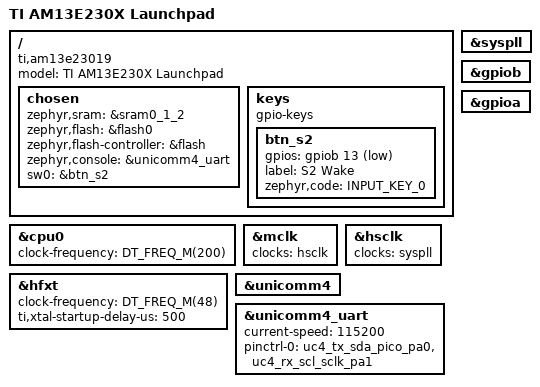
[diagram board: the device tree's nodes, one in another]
/*
 * Copyright (c) 2026 Texas Instruments Incorporated
 *
 * SPDX-License-Identifier: Apache-2.0
 */

/dts-v1/;

#include <ti/am13/am13e23019.dtsi>
#include <ti/am13/am13e23019-pinctrl.dtsi>
#include <zephyr/dt-bindings/gpio/gpio.h>
#include <zephyr/dt-bindings/input/input-event-codes.h>

/ {
	model = "TI AM13E230X Launchpad";
	compatible = "ti,am13e23019";

	chosen {
		zephyr,sram = &sram0_1_2;
		zephyr,flash = &flash0;
		zephyr,flash-controller = &flash;
		zephyr,console = &unicomm4_uart;
		sw0 = &btn_s2;
	};

	keys {
		compatible = "gpio-keys";

		/* S2: user wake/GPIO button — PB13, active low, external pull-up
		 * (LP-AM13E230 UG Table 3-x, net WAKE_GPIO / S2). */
		btn_s2: btn_s2 {
			gpios = <&gpiob 13 (GPIO_ACTIVE_LOW | GPIO_PULL_UP)>;
			label = "S2 Wake";
			zephyr,code = <INPUT_KEY_0>;
		};
	};
};

&cpu0 {
	clock-frequency = <DT_FREQ_M(200)>;
};

&mclk {
	clocks = <&hsclk>;
};

&hsclk {
	clocks = <&syspll>;
	status = "okay";
};

&syspll {
	status = "okay";
};

&hfxt {
	clock-frequency = <DT_FREQ_M(48)>;
	ti,xtal-startup-delay-us = <500>;
};

&gpiob {
	status = "okay";
};

&gpioa {
	status = "okay";
};

&unicomm4 {
	status = "okay";
};

&unicomm4_uart {
	status = "okay";
	current-speed = <115200>;
	pinctrl-0 = <&uc4_tx_sda_pico_pa0 &uc4_rx_scl_sclk_pa1>;
	pinctrl-names = "default";
};

// &unicomm3 {
// 	status = "okay";
// };

// /*
//  * CS is software (GPIO) controlled so the SPI context can keep it asserted
//  * throughout the entire pixel-data burst.  PA21 is NOT muxed to the UNICOMM
//  * CTS/CS0 function — it stays as a plain GPIO driven by the SPI context.
//  */
// &unicomm3_spi {
// 	status = "okay";
// 	pinctrl-0 = <&uc3_rx_scl_sclk_pb5
// 	             &uc3_tx_sda_pico_pb10
// 	             &uc3_rts_poci_pa20>;
// 	pinctrl-names = "default";
// 	cs-gpios = <&gpioa 21 GPIO_ACTIVE_LOW>;
// 	/* SPI frequency is set via mipi-max-frequency on the display node */
// };

// &unicomm2 {
// 	status = "okay";
// };

// &unicomm2_i2c {
// 	status = "okay";
// 	pinctrl-0 = <&uc2_tx_sda_pa22 &uc2_rx_scl_pa23>;
// 	pinctrl-names = "default";

// 	eeprom0: eeprom@54 {
// 		compatible = "zephyr,i2c-target-eeprom";
// 		reg = <0x54>;
// 		address-width = <8>;
// 		size = <256>;
// 	};
// };

// &unicomm1 {
// 	status = "okay";
// };

// &unicomm1_i2c {
// 	status = "okay";
// 	pinctrl-0 = <&uc1_tx_sda_pico_pa10 &uc1_rx_scl_sclk_pa9>;
// 	pinctrl-names = "default";

// 	eeprom1: eeprom@56 {
// 		compatible = "zephyr,i2c-target-eeprom";
// 		reg = <0x56>;
// 		address-width = <8>;
// 		size = <256>;
// 	};
// };
